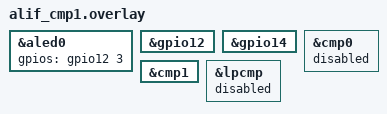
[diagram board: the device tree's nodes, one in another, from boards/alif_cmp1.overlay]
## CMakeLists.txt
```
# Copyright (C) 2024 Alif Semiconductor
# SPDX-License-Identifier: Apache-2.0

cmake_minimum_required(VERSION 3.20.0)

find_package(Zephyr REQUIRED HINTS $ENV{ZEPHYR_BASE})
project(alif_cmp)

target_sources(app PRIVATE src/main.c)


target_sources(app PRIVATE
	src/test_cmp_basic.c
	src/test_cmp_filter.c
	src/test_cmp_polarity.c
	src/test_cmp_reference.c
	src/test_cmp_feature_ext.c
	src/test_cmp_trigger.c
	src/test_cmp_output.c
	src/test_cmp_negative.c
	src/test_cmp_response_time.c
)
```

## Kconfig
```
config HY36
	bool "Enable the testcase to test Hysteresis with value 36mV"
	default n
config HY30
	bool "Enable the testcase to test Hysteresis with value 30mV"
	default n
config HY24
	bool "Enable the testcase to test Hysteresis with value 24mV"
	default n
config HY18
	bool "Enable the testcase to test Hysteresis with value 18mV"
	default n
config HY12
	bool "Enable the testcase to test Hysteresis with value 12mV"
	default n
config HY6
	bool "Enable the testcase to test Hysteresis with value 6mV"
	default n

config REF_DAC6
	bool "Enable CMP reference source test for DAC6"
	default n

config REF_VREF
	bool "Enable CMP reference source test for internal Vref"
	default n

config REF_EXT
	bool "Enable CMP reference source test for external pin"
	default n
source "Kconfig.zephyr"
```

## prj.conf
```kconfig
CONFIG_LOG=y
CONFIG_COMPARATOR=y
CONFIG_USE_ALIF_HAL_ANALOG=y
CONFIG_COMPARATOR_ALIF_COMP=y
CONFIG_ZTEST=y
```

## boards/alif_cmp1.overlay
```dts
/* Copyright (C) 2024 Alif Semiconductor - All Rights Reserved.
 * Use, distribution and modification of this code is permitted under the
 * terms stated in the Alif Semiconductor Software License Agreement
 *
 * You should have received a copy of the Alif Semiconductor Software
 * License Agreement with this file. If not, please write to:
 * contact@alifsemi.com, or visit: https://alifsemi.com/license
 */

&aled0 {
	gpios = <&gpio12 3 GPIO_ACTIVE_HIGH>;
};

&gpio12 {
	status = "okay";
};

&gpio14 {
	status = "okay";
};

&cmp0 {
	status = "disabled";
};

&cmp1 {
	status = "okay";
};

&lpcmp {
	status = "disabled";
};
```

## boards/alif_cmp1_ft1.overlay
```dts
/* Copyright (C) 2024 Alif Semiconductor - All Rights Reserved.
 * Use, distribution and modification of this code is permitted under the
 * terms stated in the Alif Semiconductor Software License Agreement
 *
 * You should have received a copy of the Alif Semiconductor Software
 * License Agreement with this file. If not, please write to:
 * contact@alifsemi.com, or visit: https://alifsemi.com/license
 */

&aled0 {
	gpios = <&gpio12 3 GPIO_ACTIVE_HIGH>;
};

&cmp1 {
	filter_taps = <1>;
	status = "okay";
};
```

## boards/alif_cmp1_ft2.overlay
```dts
/* Copyright (C) 2024 Alif Semiconductor - All Rights Reserved.
 * Use, distribution and modification of this code is permitted under the
 * terms stated in the Alif Semiconductor Software License Agreement
 *
 * You should have received a copy of the Alif Semiconductor Software
 * License Agreement with this file. If not, please write to:
 * contact@alifsemi.com, or visit: https://alifsemi.com/license
 */

&aled0 {
	gpios = <&gpio12 3 GPIO_ACTIVE_HIGH>;
};

&cmp1 {
	filter_taps = <2>;

	status = "okay";
};
```

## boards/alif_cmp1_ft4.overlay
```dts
/* Copyright (C) 2024 Alif Semiconductor - All Rights Reserved.
 * Use, distribution and modification of this code is permitted under the
 * terms stated in the Alif Semiconductor Software License Agreement
 *
 * You should have received a copy of the Alif Semiconductor Software
 * License Agreement with this file. If not, please write to:
 * contact@alifsemi.com, or visit: https://alifsemi.com/license
 */

&aled0 {
	gpios = <&gpio12 3 GPIO_ACTIVE_HIGH>;
};

&cmp1 {
	filter_taps = <4>;
	status = "okay";
};
```

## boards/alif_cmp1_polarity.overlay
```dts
/* Copyright (C) 2024 Alif Semiconductor - All Rights Reserved.
 * Use, distribution and modification of this code is permitted under the
 * terms stated in the Alif Semiconductor Software License Agreement
 *
 * You should have received a copy of the Alif Semiconductor Software
 * License Agreement with this file. If not, please write to:
 * contact@alifsemi.com, or visit: https://alifsemi.com/license
 */


&cmp1 {
	polarity_en;
	status = "okay";
};
```

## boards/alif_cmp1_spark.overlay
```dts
/* Copyright (C) 2024 Alif Semiconductor - All Rights Reserved.
 * Use, distribution and modification of this code is permitted under the
 * terms stated in the Alif Semiconductor Software License Agreement
 *
 * You should have received a copy of the Alif Semiconductor Software
 * License Agreement with this file. If not, please write to:
 * contact@alifsemi.com, or visit: https://alifsemi.com/license
 */

&aled0 {
	gpios = <&gpio4 5 GPIO_ACTIVE_HIGH>;
};

&cmp1 {
	status = "okay";
};
```

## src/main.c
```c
/* Copyright (C) 2024 Alif Semiconductor - All Rights Reserved.
 * Use, distribution and modification of this code is permitted under the
 * terms stated in the Alif Semiconductor Software License Agreement
 *
 * You should have received a copy of the Alif Semiconductor Software
 * License Agreement with this file. If not, please write to:
 * contact@alifsemi.com, or visit: https://alifsemi.com/license
 */

#include "test_cmp.h"

LOG_MODULE_REGISTER(ALIF_CMP);

/* Macros for call back */
volatile uint8_t call_back_event;
volatile uint8_t cmp_status;
uint8_t value;

void cmp_callback(const struct device *dev, void *user_data)
{
	call_back_event = 1;

#if CMP_IS_LPCMP
	/* ISR: flag only. GPIO is not ISR-safe here; other tests pass &value. */
	ARG_UNUSED(dev);
	ARG_UNUSED(user_data);
	return;
#else
	int out = comparator_get_output(dev);

	if (out >= 0) {
		cmp_status = (uint8_t)out;
		if (user_data != NULL) {
			*(uint8_t *)user_data = (uint8_t)out;
		}
	}
#endif
}

#if CMP_IS_LPCMP
static bool wait_cmp_callback_timeout(int timeout_ms)
{
	int64_t deadline = k_uptime_get() + timeout_ms;

	while (call_back_event == 0U && k_uptime_get() < deadline) {
		k_yield();
	}

	if (call_back_event == 0U) {
		return false;
	}
	call_back_event = 0U;
	return true;
}

static void wait_cmp_callback(const char *what)
{
	zassert_true(wait_cmp_callback_timeout(LPCMP_ANALOG_WAIT_MS),
		"Timed out waiting for LPCMP IRQ (%s, +%s / -%s). "
		"Drive analog POS P2_4 vs NEG P2_0 (do not jumper LED to P2_4).",
		what, CMP_POSITIVE_INPUT, CMP_NEGATIVE_INPUT);
}
#endif

void Comp_func(uint32_t loop)
{

#if defined(CONFIG_REF_EXT)
	ztest_test_skip();
	return;
#endif

	static const struct gpio_dt_spec led =
		GPIO_DT_SPEC_GET(DT_NODELABEL(aled0), gpios);
	const struct device *const cmp_dev = DEVICE_DT_GET(NODE_LABEL);
	int ret;

	zassert_true(device_is_ready(cmp_dev), "device is not ready");
	zassert_true(device_is_ready(led.port), "LED device is not ready");
	ret = gpio_pin_configure_dt(&led, GPIO_OUTPUT_LOW);
	zassert_equal(ret, 0, "Error %d: failed to configure LED pin\n", ret);
	k_msleep(2000);

	/* Drop events from a previous test before the callback is live. */
	call_back_event = 0U;
	ret = comparator_set_trigger_callback(cmp_dev, cmp_callback, &value);

	zassert_equal(ret, 0, "set_trigger_callback failed (%d)", ret);
	ret = comparator_set_trigger(cmp_dev, COMPARATOR_TRIGGER_BOTH_EDGES);
	zassert_equal(ret, 0, "set_trigger failed (%d)", ret);
	LOG_INF("start comparing");

#if CMP_IS_LPCMP
	LOG_INF("LPCMP analog + P2_4 (%s) vs - P2_0 (%s); LED aled0 glows on IRQ",
		CMP_POSITIVE_INPUT, CMP_NEGATIVE_INPUT);
	LOG_INF("Do not jumper LED to P2_4. Change POS above/below NEG within %d ms per event",
		LPCMP_ANALOG_WAIT_MS);

	while (loop--) {
		(void)gpio_pin_set_dt(&led, 0);
		/* wait_cmp_callback() consumes the flag. An IRQ during the
		 * LED glow stays set for the next wait.
		 */
		wait_cmp_callback("analog POS vs NEG");
		(void)gpio_pin_set_dt(&led, 1);
		LOG_INF("[+] LPCMP IRQ; LED on");
		k_msleep(LPCMP_LED_GLOW_MS);
		(void)gpio_pin_set_dt(&led, 0);
	}
#else
	while (loop--) {
		gpio_pin_toggle_dt(&led);

		int64_t deadline = k_uptime_get() + CMP_CALLBACK_TIMEOUT_MS;

		while (call_back_event == 0U && k_uptime_get() < deadline) {
			k_yield();
		}

		zassert_true(call_back_event != 0U,
			"Timed out waiting for comparator callback");

		call_back_event = 0U;

		cmp_status = comparator_get_output(cmp_dev);
		k_msleep(50);

		if (cmp_status == 1) {
			LOG_INF("[+] positive input voltage is greater than "
				"negative input voltage");
		} else if (cmp_status == 0) {
			LOG_INF("[-] negative input voltage is greater than the positive input "
				"voltage");
		} else {
			LOG_INF("ERROR: Status detection failed");
		}
	}
#endif

	LOG_INF("Comparison Completed");
}

void Comp_func_ref_ext(uint32_t loop)
{
	const struct device *const cmp_dev = DEVICE_DT_GET(NODE_LABEL);

	zassert_true(device_is_ready(cmp_dev), "device is not ready");

	int ret = comparator_set_trigger_callback(cmp_dev, cmp_callback, &value);

	zassert_equal(ret, 0, "set_trigger_callback failed (%d)", ret);
	ret = comparator_set_trigger(cmp_dev, COMPARATOR_TRIGGER_BOTH_EDGES);
	zassert_equal(ret, 0, "set_trigger failed (%d)", ret);
	LOG_INF("start comparing (external reference)");

	while (loop--) {
		int64_t deadline = k_uptime_get() + CMP_CALLBACK_TIMEOUT_MS;

		while (call_back_event == 0U && k_uptime_get() < deadline) {
			k_yield();
		}
		zassert_true(call_back_event != 0U,
			"Timed out waiting for comparator callback");

		call_back_event = 0U;
		cmp_status = comparator_get_output(cmp_dev);
		k_msleep(50);

		if (cmp_status == 1) {
			LOG_INF("[+] positive input voltage is greater than "
				"negative input voltage");
		} else if (cmp_status == 0) {
			LOG_INF("[-] negative input voltage is greater than "
				"the positive input voltage");
		} else {
			LOG_INF("ERROR: Status detection failed");
		}
	}

	LOG_INF("Comparison Completed (external reference)");
}
```

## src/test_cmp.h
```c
/* Copyright (C) 2024 Alif Semiconductor - All Rights Reserved.
 * Use, distribution and modification of this code is permitted under the
 * terms stated in the Alif Semiconductor Software License Agreement
 *
 * You should have received a copy of the Alif Semiconductor Software
 * License Agreement with this file. If not, please write to:
 * contact@alifsemi.com, or visit: https://alifsemi.com/license
 */

#ifndef TEST_CMP_H
#define TEST_CMP_H

#include <stdint.h>
#include <string.h>
#include <zephyr/device.h>
#include <zephyr/devicetree.h>
#include <zephyr/drivers/comparator.h>
#include <zephyr/drivers/gpio.h>
#include <zephyr/kernel.h>
#include <zephyr/logging/log.h>
#include <zephyr/ztest.h>

/*
 * Same node selection as samples/drivers/cmp: any enabled alif,cmp instance.
 * LPCMP overlay enables &lpcmp and disables high-speed CMP; CMP overlay does
 * the reverse. driver_instance enum index 0 is CMP_INSTANCE_LP.
 */
#if !DT_HAS_COMPAT_STATUS_OKAY(alif_cmp)
#error "No enabled alif,cmp node. Enable cmp0/cmp1 or lpcmp (see boards/*.overlay)."
#endif

#define NODE_LABEL DT_COMPAT_GET_ANY_STATUS_OKAY(alif_cmp)
#define CMP_NODE   NODE_LABEL

#define CMP_DRV_INSTANCE DT_ENUM_IDX(CMP_NODE, driver_instance)
#define CMP_IS_LPCMP     (CMP_DRV_INSTANCE == 0)

/*
 * LPCMP: PD0 rail-to-rail comparator. No on-chip negative (no AON/DAC6).
 * Both terminals are analog pins from pinctrl_lpcmp:
 *   +  CMP_POS_IN0..3 = P2_4..P2_7 (ANA_S20..23)
 *   -  CMP_NEG_IN0 = P2_0 (ANA_S16), IN1 = P2_1, IN2 = P2_2
 * Default test: POS P2_4 vs NEG P2_0 (CMP_NEG_IN0).
 * Not applicable: filter_taps, prescaler, polarity_en, cmp-gpios, DAC6.
 *
 * Optional properties must be gated with #if DT_NODE_HAS_PROP. A C-level
 * if () does not stop DT_PROP() from expanding, which is the LPCMP build error.
 */
#if DT_NODE_HAS_PROP(CMP_NODE, filter_taps)
#define CMP_HAS_FILTER_TAPS 1
#define CMP_FILTER_TAPS     DT_PROP(CMP_NODE, filter_taps)
#else
#define CMP_HAS_FILTER_TAPS 0
#define CMP_FILTER_TAPS     0
#endif

#if DT_NODE_HAS_PROP(CMP_NODE, prescaler)
#define CMP_HAS_PRESCALER 1
#define CMP_PRESCALER     DT_PROP(CMP_NODE, prescaler)
#else
#define CMP_HAS_PRESCALER 0
#define CMP_PRESCALER     0
#endif

/*
 * Boolean DT properties still "exist" when unset (value 0). Use the value,
 * not DT_NODE_HAS_PROP, to decide if polarity inversion is enabled.
 */
#define CMP_POLARITY_EN DT_PROP_OR(CMP_NODE, polarity_en, 0)
#if CMP_POLARITY_EN
#define CMP_HAS_POLARITY 1
#else
#define CMP_HAS_POLARITY 0
#endif

#define CMP_HAS_CMP_GPIOS  DT_NODE_HAS_PROP(CMP_NODE, cmp_gpios)
#define CMP_HYSTERESIS     DT_PROP(CMP_NODE, hysteresis_level)
#define CMP_NEGATIVE_INPUT DT_PROP(CMP_NODE, negative_input)
#define CMP_POSITIVE_INPUT DT_PROP(CMP_NODE, positive_input)

#define CMP_CALLBACK_TIMEOUT_MS 5000
#if CMP_IS_LPCMP
/* User analog on P2_4 / P2_0; LED is IRQ indicator only. */
#define LPCMP_ANALOG_WAIT_MS 20000
#define LPCMP_LED_GLOW_MS 300
#endif

extern volatile uint8_t call_back_event;
extern volatile uint8_t cmp_status;
extern uint8_t value;

void cmp_callback(const struct device *dev, void *status);
void Comp_func(uint32_t loop);
void Comp_func_ref_ext(uint32_t loop);

#endif /* TEST_CMP_H */
```

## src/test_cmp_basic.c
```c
/* Copyright (C) 2024 Alif Semiconductor - All Rights Reserved.
 * Use, distribution and modification of this code is permitted under the
 * terms stated in the Alif Semiconductor Software License Agreement
 *
 * You should have received a copy of the Alif Semiconductor Software
 * License Agreement with this file. If not, please write to:
 * contact@alifsemi.com, or visit: https://alifsemi.com/license
 */

#include "test_cmp.h"

LOG_MODULE_DECLARE(ALIF_CMP);

ZTEST(cmp_Basic, test_Comp_dt_properties)
{
	LOG_INF("CMP node properties: driver_instance idx=%d lpcmp=%d",
		CMP_DRV_INSTANCE, CMP_IS_LPCMP);
	LOG_INF("  positive_input=%s negative_input=%s hysteresis=%s",
		CMP_POSITIVE_INPUT, CMP_NEGATIVE_INPUT, CMP_HYSTERESIS);

	zassert_true(DT_NODE_HAS_PROP(CMP_NODE, driver_instance),
		"driver_instance is required");
	zassert_true(DT_NODE_HAS_PROP(CMP_NODE, positive_input),
		"positive_input is required");
	zassert_true(DT_NODE_HAS_PROP(CMP_NODE, negative_input),
		"negative_input is required");
	zassert_true(DT_NODE_HAS_PROP(CMP_NODE, hysteresis_level),
		"hysteresis_level is required");

	if (CMP_IS_LPCMP) {
		zassert_false(CMP_HAS_FILTER_TAPS,
			"filter_taps is not applicable to LPCMP");
		zassert_false(CMP_HAS_PRESCALER,
			"prescaler is not applicable to LPCMP");
		/*
		 * polarity_en is a boolean in the alif,cmp binding, so
		 * DT_NODE_HAS_PROP() can be true even when the overlay does
		 * not set it (value is 0). LPCMP does not program polarity;
		 * only require that inversion is not enabled.
		 */
		zassert_false(CMP_POLARITY_EN,
			"LPCMP must not enable polarity inversion");
		zassert_false(CMP_HAS_CMP_GPIOS,
			"cmp-gpios is not applicable to LPCMP (no board output pinout)");
		LOG_INF("LPCMP: filter/prescaler/cmp-gpios omitted, polarity_en=%d",
			CMP_POLARITY_EN);
	} else {
		zassert_true(CMP_HAS_FILTER_TAPS,
			"filter_taps is required for high-speed CMP");
		zassert_true(CMP_HAS_PRESCALER,
			"prescaler is required for high-speed CMP");
		zassert_true(CMP_HAS_CMP_GPIOS,
			"cmp-gpios is required for high-speed CMP output");
		LOG_INF("CMP: filter_taps=%d prescaler=%d polarity_en=%d",
			CMP_FILTER_TAPS, CMP_PRESCALER, CMP_POLARITY_EN);
	}
}

ZTEST(cmp_Basic, test_Comp_BasicTest)
{
	LOG_INF("Basic test with hysteresis %s", CMP_HYSTERESIS);
	Comp_func(20);
}

ZTEST(cmp_Basic, test_Comp_prescaler_min_max)
{
#if !CMP_HAS_PRESCALER
	LOG_INF("Skipping prescaler test: not applicable to this instance");
	ztest_test_skip();
#else
	zassert_true((CMP_PRESCALER >= 0) && (CMP_PRESCALER <= 63),
		"Prescaler out of range: %d", CMP_PRESCALER);
#endif
}

ZTEST(cmp_Basic, test_Comp_SampleApp)
{
	Comp_func(6);
}

ZTEST_SUITE(cmp_Basic, NULL, NULL, NULL, NULL, NULL);
```

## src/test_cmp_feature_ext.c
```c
/* Copyright (C) 2024 Alif Semiconductor - All Rights Reserved.
 * Use, distribution and modification of this code is permitted under the
 * terms stated in the Alif Semiconductor Software License Agreement
 *
 * You should have received a copy of the Alif Semiconductor Software
 * License Agreement with this file. If not, please write to:
 * contact@alifsemi.com, or visit: https://alifsemi.com/license
 */

#include "test_cmp.h"

LOG_MODULE_DECLARE(ALIF_CMP);

ZTEST(cmp_Hysteresis, test_Comp_Hys_0mV)
{
	if (strcmp(CMP_HYSTERESIS, "0mV") != 0) {
		ztest_test_skip();
	}
	Comp_func(4);
}

ZTEST(cmp_Hysteresis, test_Comp_Hys_6mV)
{
	if (strcmp(CMP_HYSTERESIS, "6mV") != 0) {
		ztest_test_skip();
	}
	Comp_func(4);
}

ZTEST(cmp_Hysteresis, test_Comp_Hys_12mV)
{
	if (strcmp(CMP_HYSTERESIS, "12mV") != 0) {
		ztest_test_skip();
	}
	Comp_func(4);
}

ZTEST(cmp_Hysteresis, test_Comp_Hys_18mV)
{
	if (strcmp(CMP_HYSTERESIS, "18mV") != 0) {
		ztest_test_skip();
	}
	Comp_func(4);
}

ZTEST(cmp_Hysteresis, test_Comp_Hys_24mV)
{
	if (strcmp(CMP_HYSTERESIS, "24mV") != 0) {
		ztest_test_skip();
	}
	Comp_func(4);
}

ZTEST(cmp_Hysteresis, test_Comp_Hys_30mV)
{
	if (strcmp(CMP_HYSTERESIS, "30mV") != 0) {
		ztest_test_skip();
	}
	Comp_func(4);
}

ZTEST(cmp_Hysteresis, test_Comp_Hys_36mV)
{
	if (strcmp(CMP_HYSTERESIS, "36mV") != 0) {
		ztest_test_skip();
	}
	Comp_func(4);
}

ZTEST_SUITE(cmp_Hysteresis, NULL, NULL, NULL, NULL, NULL);

ZTEST(cmp_FeatureExt, test_Comp_windowing_feature)
{
	ztest_test_skip();
}

ZTEST_SUITE(cmp_FeatureExt, NULL, NULL, NULL, NULL, NULL);
```

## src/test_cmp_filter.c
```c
/* Copyright (C) 2024 Alif Semiconductor - All Rights Reserved.
 * Use, distribution and modification of this code is permitted under the
 * terms stated in the Alif Semiconductor Software License Agreement
 *
 * You should have received a copy of the Alif Semiconductor Software
 * License Agreement with this file. If not, please write to:
 * contact@alifsemi.com, or visit: https://alifsemi.com/license
 */

#include "test_cmp.h"

LOG_MODULE_DECLARE(ALIF_CMP);

ZTEST(cmp_Filter, test_Comp_filter_taps_4)
{
#if !CMP_HAS_FILTER_TAPS
	ztest_test_skip();
#else
	if (CMP_FILTER_TAPS != 4) {
		ztest_test_skip();
	}
	Comp_func(3);
#endif
}

ZTEST(cmp_Filter, test_Comp_filter_taps_3)
{
#if !CMP_HAS_FILTER_TAPS
	ztest_test_skip();
#else
	if (CMP_FILTER_TAPS != 3) {
		ztest_test_skip();
	}
	Comp_func(5);
#endif
}

ZTEST(cmp_Filter, test_Comp_filter_taps_2)
{
#if !CMP_HAS_FILTER_TAPS
	ztest_test_skip();
#else
	if (CMP_FILTER_TAPS != 2) {
		ztest_test_skip();
	}
	Comp_func(5);
#endif
}

ZTEST(cmp_Filter, test_Comp_filter_taps_1)
{
#if !CMP_HAS_FILTER_TAPS
	ztest_test_skip();
#else
	if (CMP_FILTER_TAPS != 1) {
		ztest_test_skip();
	}
	Comp_func(4);
#endif
}

ZTEST(cmp_Filter, test_Comp_filter_taps_invalid)
{
#if !CMP_HAS_FILTER_TAPS
	ztest_test_skip();
#else
	if (CMP_FILTER_TAPS >= 1 && CMP_FILTER_TAPS <= 4) {
		ztest_test_skip();
	}
	zassert_true((CMP_FILTER_TAPS < 1) || (CMP_FILTER_TAPS > 4),
		"Expected invalid filter taps configuration");
#endif
}

ZTEST(cmp_Filter, test_Comp_Int_gen_after_filtering)
{
#if !CMP_HAS_FILTER_TAPS
	ztest_test_skip();
#else
	const struct device *const dev = DEVICE_DT_GET(NODE_LABEL);
	int ret;

	zassert_true(device_is_ready(dev), "CMP device not ready");
	ret = comparator_set_trigger_callback(dev, cmp_callback, &value);
	zassert_equal(ret, 0, "set_trigger_callback failed (%d)", ret);
	ret = comparator_set_trigger(dev, COMPARATOR_TRIGGER_BOTH_EDGES);
	zassert_equal(ret, 0, "set_trigger failed (%d)", ret);

	Comp_func(3);
#endif
}

ZTEST_SUITE(cmp_Filter, NULL, NULL, NULL, NULL, NULL);
```

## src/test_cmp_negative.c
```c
/* Copyright (C) 2024 Alif Semiconductor - All Rights Reserved.
 * Use, distribution and modification of this code is permitted under the
 * terms stated in the Alif Semiconductor Software License Agreement
 *
 * You should have received a copy of the Alif Semiconductor Software
 * License Agreement with this file. If not, please write to:
 * contact@alifsemi.com, or visit: https://alifsemi.com/license
 */

#include "test_cmp.h"

LOG_MODULE_DECLARE(ALIF_CMP);

ZTEST(cmp_Negative, test_cmp_device_ready)
{
	const struct device *const dev = DEVICE_DT_GET(NODE_LABEL);

	zassert_true(device_is_ready(dev),
		"CMP device should be ready after init");
	LOG_INF("Device readiness check passed");
}

ZTEST(cmp_Negative, test_Comp_set_trigger_without_callback)
{
	const struct device *const dev = DEVICE_DT_GET(NODE_LABEL);
	int ret;

	zassert_true(device_is_ready(dev), "CMP device not ready");

	/* Disable callback first */
	ret = comparator_set_trigger_callback(dev, NULL, NULL);
	zassert_equal(ret, 0, "set_trigger_callback(NULL) failed (%d)", ret);

	/* Set trigger without a callback registered */
	ret = comparator_set_trigger(dev, COMPARATOR_TRIGGER_BOTH_EDGES);
	zassert_equal(ret, 0, "set_trigger should succeed even without callback (%d)", ret);
	LOG_INF("Trigger without callback: returned %d", ret);
}

ZTEST(cmp_Negative, test_get_output_multiple_reads)
{
	if (CMP_IS_LPCMP || !CMP_HAS_CMP_GPIOS) {
		ztest_test_skip();
	}

	const struct device *const dev = DEVICE_DT_GET(NODE_LABEL);
	int ret1, ret2;

	zassert_true(device_is_ready(dev), "CMP device not ready");

	ret1 = comparator_get_output(dev);
	zassert_true((ret1 == 0) || (ret1 == 1),
		"First read unexpected value %d", ret1);

	/* Back-to-back read should not crash or return error */
	ret2 = comparator_get_output(dev);
	zassert_true((ret2 == 0) || (ret2 == 1),
		"Second read unexpected value %d", ret2);

	LOG_INF("Multiple reads: %d, %d", ret1, ret2);
}

ZTEST(cmp_Negative, test_trigger_is_pending_no_event)
{
	if (CMP_IS_LPCMP) {
		ztest_test_skip();
	}

	const struct device *const dev = DEVICE_DT_GET(NODE_LABEL);
	int ret;

	zassert_true(device_is_ready(dev), "CMP device not ready");

	ret = comparator_set_trigger_callback(dev, NULL, NULL);
	zassert_equal(ret, 0, "set_trigger_callback(NULL) failed (%d)", ret);

	ret = comparator_set_trigger(dev, COMPARATOR_TRIGGER_NONE);
	zassert_equal(ret, 0, "set_trigger NONE failed (%d)", ret);

	/*
	 * trigger_is_pending() checks and clears. Earlier tests leave
	 * BOTH_EDGES armed, so a leftover pending bit is expected.
	 */
	ret = comparator_trigger_is_pending(dev);
	zassert_true((ret == 0) || (ret == 1),
		"trigger_is_pending unexpected value %d", ret);

	ret = comparator_trigger_is_pending(dev);
	zassert_equal(ret, 0,
		"trigger_is_pending should be 0 after clear with TRIGGER_NONE (%d)",
		ret);
	LOG_INF("Pending after TRIGGER_NONE: %d", ret);
}

ZTEST(cmp_Negative, test_callback_overwrite)
{
	const struct device *const dev = DEVICE_DT_GET(NODE_LABEL);
	int ret;

	zassert_true(device_is_ready(dev), "CMP device not ready");

	/* Set callback */
	ret = comparator_set_trigger_callback(dev, cmp_callback, &value);
	zassert_equal(ret, 0, "First set_trigger_callback failed (%d)", ret);

	/* Overwrite with NULL - should not crash */
	ret = comparator_set_trigger_callback(dev, NULL, NULL);
	zassert_equal(ret, 0, "Overwrite callback to NULL failed (%d)", ret);

	/* Set callback again - should work */
	ret = comparator_set_trigger_callback(dev, cmp_callback, &value);
	zassert_equal(ret, 0, "Re-set callback failed (%d)", ret);

	LOG_INF("Callback overwrite sequence OK");
}

ZTEST_SUITE(cmp_Negative, NULL, NULL, NULL, NULL, NULL);
```

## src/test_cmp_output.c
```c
/* Copyright (C) 2024 Alif Semiconductor - All Rights Reserved.
 * Use, distribution and modification of this code is permitted under the
 * terms stated in the Alif Semiconductor Software License Agreement
 *
 * You should have received a copy of the Alif Semiconductor Software
 * License Agreement with this file. If not, please write to:
 * contact@alifsemi.com, or visit: https://alifsemi.com/license
 */

#include "test_cmp.h"

LOG_MODULE_DECLARE(ALIF_CMP);

ZTEST(cmp_Output, test_Comp_get_output_ready)
{
	if (CMP_IS_LPCMP || !CMP_HAS_CMP_GPIOS) {
		ztest_test_skip();
	}

	const struct device *const dev = DEVICE_DT_GET(NODE_LABEL);
	int ret;

	zassert_true(device_is_ready(dev), "CMP device not ready");

	ret = comparator_get_output(dev);
	zassert_true((ret == 0) || (ret == 1),
		"comparator_get_output returned unexpected value %d", ret);
	LOG_INF("CMP output state: %d", ret);
}

ZTEST(cmp_Output, test_Comp_get_output_after_trigger)
{
	if (CMP_IS_LPCMP || !CMP_HAS_CMP_GPIOS) {
		ztest_test_skip();
	}

	const struct device *const dev = DEVICE_DT_GET(NODE_LABEL);
	int ret;

	zassert_true(device_is_ready(dev), "CMP device not ready");

	ret = comparator_set_trigger_callback(dev, cmp_callback, &value);
	zassert_equal(ret, 0, "set_trigger_callback failed (%d)", ret);

	ret = comparator_set_trigger(dev, COMPARATOR_TRIGGER_BOTH_EDGES);
	zassert_equal(ret, 0, "set_trigger failed (%d)", ret);

	ret = comparator_get_output(dev);
	zassert_true((ret == 0) || (ret == 1),
		"comparator_get_output returned unexpected value %d", ret);
	LOG_INF("CMP output after trigger setup: %d", ret);
}

ZTEST(cmp_Output, test_Comp_trigger_is_pending_clear)
{
	if (CMP_IS_LPCMP) {
		ztest_test_skip();
	}

	const struct device *const dev = DEVICE_DT_GET(NODE_LABEL);
	int ret;

	zassert_true(device_is_ready(dev), "CMP device not ready");

	ret = comparator_trigger_is_pending(dev);
	zassert_true((ret == 0) || (ret == 1),
		"trigger_is_pending returned unexpected value %d", ret);
	LOG_INF("Trigger pending state: %d", ret);
}

ZTEST(cmp_Output, test_Comp_get_output_stability)
{
	if (CMP_IS_LPCMP || !CMP_HAS_CMP_GPIOS) {
		ztest_test_skip();
	}

	const struct device *const dev = DEVICE_DT_GET(NODE_LABEL);
	int r1, r2, r3;

	zassert_true(device_is_ready(dev), "CMP device not ready");

	r1 = comparator_get_output(dev);
	r2 = comparator_get_output(dev);
	r3 = comparator_get_output(dev);

	zassert_true((r1 == 0) || (r1 == 1), "Unexpected output r1=%d", r1);
	zassert_true((r2 == 0) || (r2 == 1), "Unexpected output r2=%d", r2);
	zassert_true((r3 == 0) || (r3 == 1), "Unexpected output r3=%d", r3);
}

ZTEST(cmp_Output, test_Comp_trigger_pending_after_none)
{
	if (CMP_IS_LPCMP) {
		ztest_test_skip();
	}

	const struct device *const dev = DEVICE_DT_GET(NODE_LABEL);
	int ret;

	zassert_true(device_is_ready(dev), "CMP device not ready");

	ret = comparator_set_trigger(dev, COMPARATOR_TRIGGER_NONE);
	zassert_equal(ret, 0, "set_trigger NONE failed (%d)", ret);

	ret = comparator_trigger_is_pending(dev);
	zassert_true((ret == 0) || (ret == 1),
		"trigger_is_pending unexpected value %d", ret);
}

ZTEST(cmp_Output, test_Comp_null_callback)
{
	const struct device *const dev = DEVICE_DT_GET(NODE_LABEL);
	int ret;

	zassert_true(device_is_ready(dev), "CMP device not ready");

	/* Setting callback to NULL should disable callbacks per Zephyr API */
	ret = comparator_set_trigger_callback(dev, NULL, NULL);
	zassert_equal(ret, 0, "set_trigger_callback(NULL) failed (%d)", ret);
	LOG_INF("Callback disabled (NULL) OK");
}

ZTEST_SUITE(cmp_Output, NULL, NULL, NULL, NULL, NULL);
```

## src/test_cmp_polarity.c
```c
/* Copyright (C) 2024 Alif Semiconductor - All Rights Reserved.
 * Use, distribution and modification of this code is permitted under the
 * terms stated in the Alif Semiconductor Software License Agreement
 *
 * You should have received a copy of the Alif Semiconductor Software
 * License Agreement with this file. If not, please write to:
 * contact@alifsemi.com, or visit: https://alifsemi.com/license
 */

#include "test_cmp.h"

LOG_MODULE_DECLARE(ALIF_CMP);

ZTEST(cmp_Polarity, test_Comp_Polarity)
{
#if !CMP_HAS_POLARITY
	TC_PRINT("Skipping polarity test: polarity_en is not applicable/enabled\n");
	ztest_test_skip();
#else
	if (!CMP_POLARITY_EN) {
		TC_PRINT("Skipping polarity test: polarity_en is not applicable/enabled\n");
		ztest_test_skip();
		return;
	}

	Comp_func(5);
#endif
}

ZTEST_SUITE(cmp_Polarity, NULL, NULL, NULL, NULL, NULL);
```

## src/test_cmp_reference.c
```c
/* Copyright (C) 2024 Alif Semiconductor - All Rights Reserved.
 * Use, distribution and modification of this code is permitted under the
 * terms stated in the Alif Semiconductor Software License Agreement
 *
 * You should have received a copy of the Alif Semiconductor Software
 * License Agreement with this file. If not, please write to:
 * contact@alifsemi.com, or visit: https://alifsemi.com/license
 */

#include "test_cmp.h"

LOG_MODULE_DECLARE(ALIF_CMP);

ZTEST(cmp_Reference, test_Comp_ref_dac6)
{
	if (CMP_IS_LPCMP) {
		LOG_INF("Skipping DAC6: LPCMP has no internal negative");
		ztest_test_skip();
	}
#if defined(CONFIG_REF_DAC6)
	zassert_true(!strcmp(CMP_NEGATIVE_INPUT, "CMP_NEG_IN3"),
		"Expected negative_input CMP_NEG_IN3 for DAC6, got %s", CMP_NEGATIVE_INPUT);
	LOG_INF("CMP reference test: DAC6 via %s", CMP_NEGATIVE_INPUT);
	Comp_func(6);
#else
	ztest_test_skip();
#endif
}

ZTEST(cmp_Reference, test_Comp_int_vref)
{
#if CMP_IS_LPCMP
	LOG_INF("Skipping internal Vref: LPCMP negative is an external analog pin");
	ztest_test_skip();
#else
#if defined(CONFIG_REF_VREF)
	zassert_true(!strcmp(CMP_NEGATIVE_INPUT, "CMP_NEG_IN2"),
		"Expected negative_input CMP_NEG_IN2 for internal Vref, got %s",
		CMP_NEGATIVE_INPUT);
	LOG_INF("CMP reference test: internal Vref via %s", CMP_NEGATIVE_INPUT);
	Comp_func(6);
#else
	ztest_test_skip();
#endif
#endif
}

ZTEST(cmp_Reference, test_Comp_ref_external_pin)
{
#if CMP_IS_LPCMP
	zassert_true(!strcmp(CMP_NEGATIVE_INPUT, "CMP_NEG_IN0"),
		"Expected negative_input CMP_NEG_IN0 for LPCMP external pin (P2_0), got %s",
		CMP_NEGATIVE_INPUT);
	LOG_INF("LPCMP reference: external pin via %s (DC on P2_0)",
		CMP_NEGATIVE_INPUT);
	Comp_func(6);
#else
#if defined(CONFIG_REF_EXT)
	zassert_true(!strcmp(CMP_NEGATIVE_INPUT, "CMP_NEG_IN0"),
		"Expected negative_input CMP_NEG_IN0 for external pin, got %s", CMP_NEGATIVE_INPUT);
	LOG_INF("CMP reference test: external pin via %s", CMP_NEGATIVE_INPUT);
	Comp_func_ref_ext(6);
#else
	ztest_test_skip();
#endif
#endif
}

ZTEST_SUITE(cmp_Reference, NULL, NULL, NULL, NULL, NULL);
```

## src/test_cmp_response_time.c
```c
/* Copyright (C) 2024 Alif Semiconductor - All Rights Reserved.
 * Use, distribution and modification of this code is permitted under the
 * terms stated in the Alif Semiconductor Software License Agreement
 *
 * You should have received a copy of the Alif Semiconductor Software
 * License Agreement with this file. If not, please write to:
 * contact@alifsemi.com, or visit: https://alifsemi.com/license
 */

#include "test_cmp.h"

LOG_MODULE_DECLARE(ALIF_CMP);

ZTEST(cmp_ResponseTime, test_Comp_response_time_manual_hw_validation)
{
	const struct device *const cmp_dev = DEVICE_DT_GET(NODE_LABEL);
	int ret;

	zassert_true(device_is_ready(cmp_dev), "CMP device is not ready");

	ret = comparator_set_trigger_callback(cmp_dev, cmp_callback, &value);
	zassert_equal(ret, 0, "set_trigger_callback failed (%d)", ret);

	ret = comparator_set_trigger(cmp_dev, COMPARATOR_TRIGGER_BOTH_EDGES);
	zassert_equal(ret, 0, "set_trigger failed (%d)", ret);

	LOG_INF("CMP/LPCMP response-time feature is configured");
	LOG_INF("Manual validation required: measure propagation delay with scope");
	if (CMP_IS_LPCMP) {
		LOG_INF("Pass criteria (LPCMP HRM): propagation delay < 10 us");
	} else {
		LOG_INF("Pass criteria (CMP): comparator propagation delay < 5 ns");
	}

	ztest_test_skip();
}

ZTEST_SUITE(cmp_ResponseTime, NULL, NULL, NULL, NULL, NULL);
```

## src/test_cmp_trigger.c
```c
/* Copyright (C) 2024 Alif Semiconductor - All Rights Reserved.
 * Use, distribution and modification of this code is permitted under the
 * terms stated in the Alif Semiconductor Software License Agreement
 *
 * You should have received a copy of the Alif Semiconductor Software
 * License Agreement with this file. If not, please write to:
 * contact@alifsemi.com, or visit: https://alifsemi.com/license
 */

#include "test_cmp.h"

LOG_MODULE_DECLARE(ALIF_CMP);

ZTEST(cmp_Trigger, test_Comp_trigger_both_edges)
{
	const struct device *const dev = DEVICE_DT_GET(NODE_LABEL);
	int ret;

	zassert_true(device_is_ready(dev), "CMP device not ready");
	ret = comparator_set_trigger_callback(dev, cmp_callback, &value);
	zassert_equal(ret, 0, "set_trigger_callback failed (%d)", ret);
	ret = comparator_set_trigger(dev, COMPARATOR_TRIGGER_BOTH_EDGES);
	zassert_equal(ret, 0, "set_trigger BOTH_EDGES failed (%d)", ret);
	LOG_INF("Trigger BOTH_EDGES OK");
}

ZTEST(cmp_Trigger, test_Comp_trigger_rising_edge)
{
	const struct device *const dev = DEVICE_DT_GET(NODE_LABEL);
	int ret;

	zassert_true(device_is_ready(dev), "CMP device not ready");
	ret = comparator_set_trigger_callback(dev, cmp_callback, &value);
	zassert_equal(ret, 0, "set_trigger_callback failed (%d)", ret);
	ret = comparator_set_trigger(dev, COMPARATOR_TRIGGER_RISING_EDGE);
	zassert_equal(ret, 0, "set_trigger RISING_EDGE failed (%d)", ret);
	LOG_INF("Trigger RISING_EDGE OK");
}

ZTEST(cmp_Trigger, test_Comp_trigger_falling_edge)
{
	const struct device *const dev = DEVICE_DT_GET(NODE_LABEL);
	int ret;

	zassert_true(device_is_ready(dev), "CMP device not ready");
	ret = comparator_set_trigger_callback(dev, cmp_callback, &value);
	zassert_equal(ret, 0, "set_trigger_callback failed (%d)", ret);
	ret = comparator_set_trigger(dev, COMPARATOR_TRIGGER_FALLING_EDGE);
	zassert_equal(ret, 0, "set_trigger FALLING_EDGE failed (%d)", ret);
	LOG_INF("Trigger FALLING_EDGE OK");
}

ZTEST(cmp_Trigger, test_Comp_trigger_none)
{
	const struct device *const dev = DEVICE_DT_GET(NODE_LABEL);
	int ret;

	zassert_true(device_is_ready(dev), "CMP device not ready");
	ret = comparator_set_trigger(dev, COMPARATOR_TRIGGER_NONE);
	zassert_equal(ret, 0, "set_trigger NONE failed (%d)", ret);
	LOG_INF("Trigger NONE OK");
}

ZTEST(cmp_Trigger, test_Comp_trigger_mode_switch_sequence)
{
	const struct device *const dev = DEVICE_DT_GET(NODE_LABEL);
	int ret;

	zassert_true(device_is_ready(dev), "CMP device not ready");
	ret = comparator_set_trigger_callback(dev, cmp_callback, &value);
	zassert_equal(ret, 0, "set_trigger_callback failed (%d)", ret);

	ret = comparator_set_trigger(dev, COMPARATOR_TRIGGER_RISING_EDGE);
	zassert_equal(ret, 0, "set_trigger RISING_EDGE failed (%d)", ret);
	ret = comparator_set_trigger(dev, COMPARATOR_TRIGGER_FALLING_EDGE);
	zassert_equal(ret, 0, "set_trigger FALLING_EDGE failed (%d)", ret);
	ret = comparator_set_trigger(dev, COMPARATOR_TRIGGER_BOTH_EDGES);
	zassert_equal(ret, 0, "set_trigger BOTH_EDGES failed (%d)", ret);
	ret = comparator_set_trigger(dev, COMPARATOR_TRIGGER_NONE);
	zassert_equal(ret, 0, "set_trigger NONE failed (%d)", ret);
}

ZTEST(cmp_Trigger, test_Comp_trigger_with_null_callback)
{
	const struct device *const dev = DEVICE_DT_GET(NODE_LABEL);
	int ret;

	zassert_true(device_is_ready(dev), "CMP device not ready");
	ret = comparator_set_trigger_callback(dev, NULL, NULL);
	zassert_equal(ret, 0, "set_trigger_callback(NULL) failed (%d)", ret);
	ret = comparator_set_trigger(dev, COMPARATOR_TRIGGER_BOTH_EDGES);
	zassert_equal(ret, 0, "set_trigger BOTH_EDGES with NULL callback failed (%d)", ret);
}

ZTEST(cmp_Trigger, test_Comp_start_twice)
{
	const struct device *const dev = DEVICE_DT_GET(NODE_LABEL);
	int ret;

	zassert_true(device_is_ready(dev), "CMP device not ready");
	ret = comparator_set_trigger(dev, COMPARATOR_TRIGGER_BOTH_EDGES);
	zassert_equal(ret, 0, "first set_trigger failed (%d)", ret);
	ret = comparator_set_trigger(dev, COMPARATOR_TRIGGER_BOTH_EDGES);
	zassert_equal(ret, 0, "second set_trigger failed (%d)", ret);
}

ZTEST(cmp_Trigger, test_Comp_rapid_callback)
{
	const struct device *const dev = DEVICE_DT_GET(NODE_LABEL);
	int ret;

	zassert_true(device_is_ready(dev), "CMP device not ready");
	ret = comparator_set_trigger_callback(dev, cmp_callback, &value);
	zassert_equal(ret, 0, "set_trigger_callback failed (%d)", ret);
	ret = comparator_set_trigger(dev, COMPARATOR_TRIGGER_BOTH_EDGES);
	zassert_equal(ret, 0, "set_trigger failed (%d)", ret);

	Comp_func(2);
}

ZTEST_SUITE(cmp_Trigger, NULL, NULL, NULL, NULL, NULL);
```
